# IODELAYCONFIG register map
Vendor: Texas Instruments
Registers are 32-bit, access per field, reset 0x0 unless marked. A register's access mark holds for its fields unless they carry their own. Offsets are as the file gives them; [hi:lo] are bit positions; {n}, {i} and the like mark numbered series; 'fields as' and 'values as' point back to an identical list.

## IODELAYCONFIG (part 2 of 2)
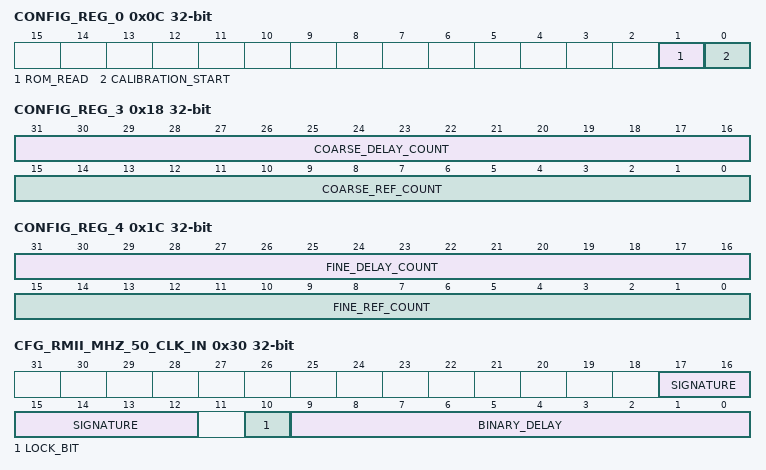
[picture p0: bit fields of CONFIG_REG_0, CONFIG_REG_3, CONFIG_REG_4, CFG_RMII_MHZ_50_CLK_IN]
0x0C CONFIG_REG_0 — Calibration Control Register
  [1] ROM_READ rw — Triggers complete ROM read when '1' is written. Cleared when ROM read is complete.
  [0] CALIBRATION_START rw — Triggers hardware calibration when '1' is written. Cleared when hardware completes calibration.
0x14 CONFIG_REG_2 reset 0x21D2 — Reference Clock Period Register.
  [15:0] REFCLK_PERIOD rw — 15:0 stores the binary equivalent of reference clock period in units of 10ps. This value (along with calibration results) is used for computing the coarse/fine element delay Example: 0xF0 means 2400ps.
0x18 CONFIG_REG_3 rw — coarse calibration results register
  [31:16] COARSE_DELAY_COUNT — Results of 16 bit counter clocked by 'delay line oscillator' clock during calibration.
  [15:0] COARSE_REF_COUNT — Results of 16 bit counter clocked by 'reference' clock during coarse calibration.
0x1C CONFIG_REG_4 rw — fine calibration results register
  [31:16] FINE_DELAY_COUNT — Results of 16 bit counter clocked by 'delay line oscillator' clock during fine calibration.
  [15:0] FINE_REF_COUNT — Results of 16 bit counter clocked by 'reference' clock during fine calibration.
0x2C CONFIG_REG_8 reset 0x1 — Global Lock Register.
  [0] GLOBAL_LOCK_BIT rw — Global Lock Bit Register. A '1' in this bit protects the writes to MMRs that store delay line select values. A '0' in this bit indicates that MMRs that store delay line select values are writeable. To write a '0' to this bit, signature of 0x5555 must be used on the MSB bits 16:1 of mdata.
0x30 CFG_RMII_MHZ_50_CLK_IN — Delay Select Value in binary coded form for cfg_RMII_MHZ_50_CLK_in interface
  [17:12] SIGNATURE rw — Write to this register will succeed only if data on these bits carries a signature of 6'h29 (6'b101001)
  [10] LOCK_BIT rw — When '1', prevents HW update to this MMR. When '0', allows HW update of this MMR.
  [9:0] BINARY_DELAY rw — Delay Select Value in binary coded form. Indicates the number of coarse (9:5) and fine (4:0) delay elements to be used on the delay line connected to this pad.
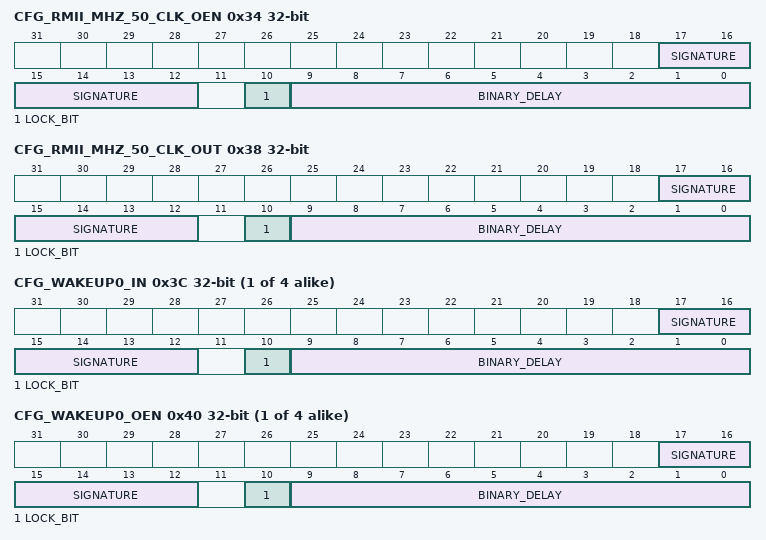
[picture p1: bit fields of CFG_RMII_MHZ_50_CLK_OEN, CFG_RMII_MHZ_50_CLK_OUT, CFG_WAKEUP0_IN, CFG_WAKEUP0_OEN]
0x34 CFG_RMII_MHZ_50_CLK_OEN — Delay Select Value in binary coded form for cfg_RMII_MHZ_50_CLK_oen interface
  fields as CFG_RMII_MHZ_50_CLK_IN
0x38 CFG_RMII_MHZ_50_CLK_OUT — Delay Select Value in binary coded form for cfg_RMII_MHZ_50_CLK_out interface
  fields as CFG_RMII_MHZ_50_CLK_IN
{0x3C+0xC*i} CFG_WAKEUP{i}_IN (i=0..3) — Delay Select Value in binary coded form for cfg_Wakeup{i}_in interface
  fields as CFG_RMII_MHZ_50_CLK_IN
{0x40+0xC*i} CFG_WAKEUP{i}_OEN (i=0..3) — Delay Select Value in binary coded form for cfg_Wakeup{i}_oen interface
  fields as CFG_RMII_MHZ_50_CLK_IN
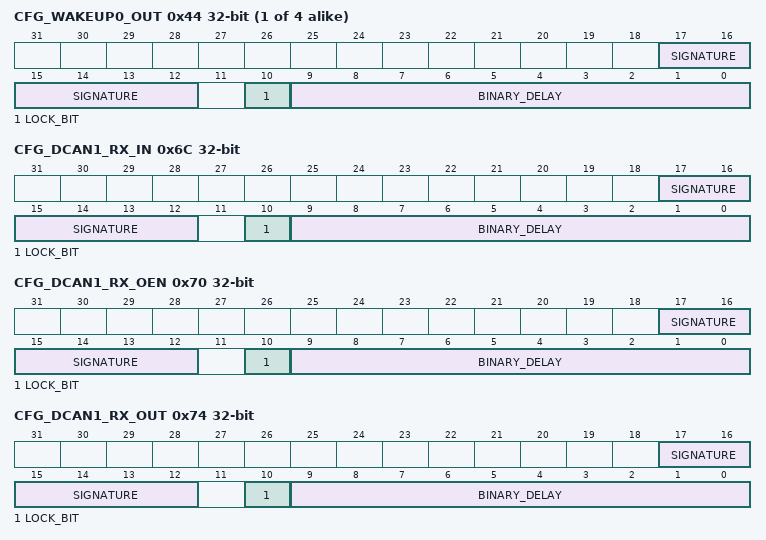
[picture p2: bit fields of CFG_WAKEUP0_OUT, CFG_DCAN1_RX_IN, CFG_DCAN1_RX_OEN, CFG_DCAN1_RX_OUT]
{0x44+0xC*i} CFG_WAKEUP{i}_OUT (i=0..3) — Delay Select Value in binary coded form for cfg_Wakeup{i}_out interface
  fields as CFG_RMII_MHZ_50_CLK_IN
0x6C CFG_DCAN1_RX_IN — Delay Select Value in binary coded form for cfg_dcan1_rx_in interface
  fields as CFG_RMII_MHZ_50_CLK_IN
0x70 CFG_DCAN1_RX_OEN — Delay Select Value in binary coded form for cfg_dcan1_rx_oen interface
  fields as CFG_RMII_MHZ_50_CLK_IN
0x74 CFG_DCAN1_RX_OUT — Delay Select Value in binary coded form for cfg_dcan1_rx_out interface
  fields as CFG_RMII_MHZ_50_CLK_IN
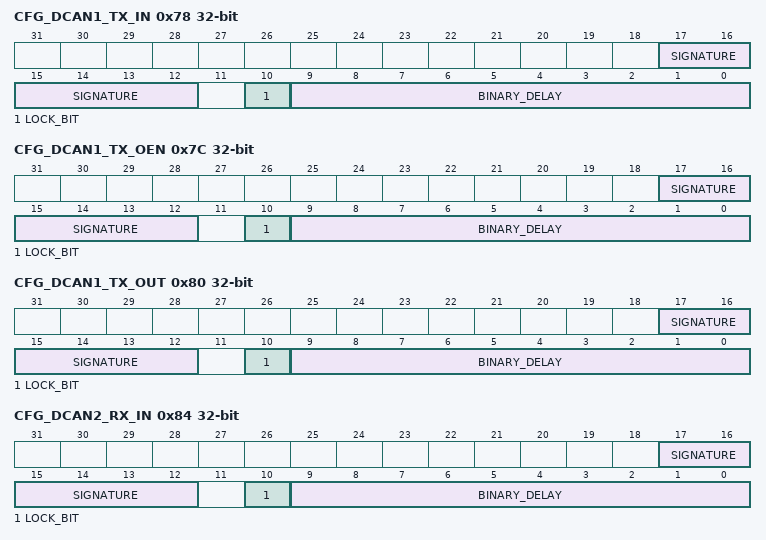
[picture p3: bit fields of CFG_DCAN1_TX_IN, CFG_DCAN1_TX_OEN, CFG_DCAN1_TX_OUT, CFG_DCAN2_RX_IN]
0x78 CFG_DCAN1_TX_IN — Delay Select Value in binary coded form for cfg_dcan1_tx_in interface
  fields as CFG_RMII_MHZ_50_CLK_IN
0x7C CFG_DCAN1_TX_OEN — Delay Select Value in binary coded form for cfg_dcan1_tx_oen interface
  fields as CFG_RMII_MHZ_50_CLK_IN
0x80 CFG_DCAN1_TX_OUT — Delay Select Value in binary coded form for cfg_dcan1_tx_out interface
  fields as CFG_RMII_MHZ_50_CLK_IN
0x84 CFG_DCAN2_RX_IN — Delay Select Value in binary coded form for cfg_dcan2_rx_in interface
  fields as CFG_RMII_MHZ_50_CLK_IN
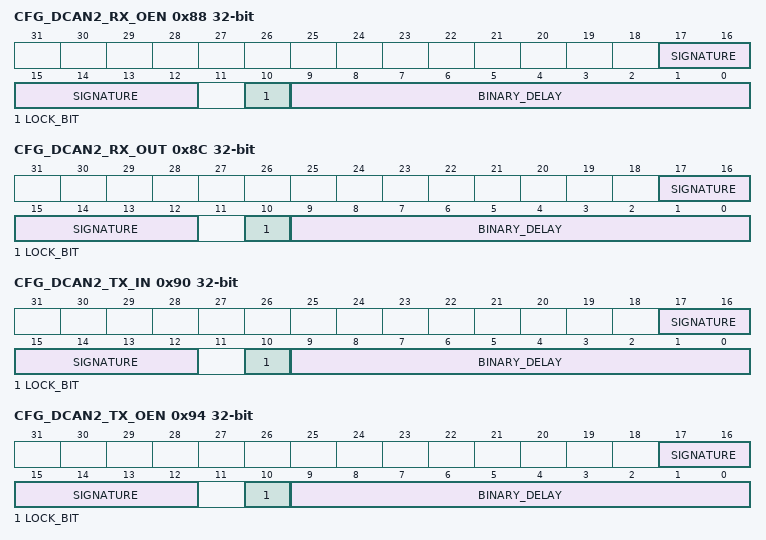
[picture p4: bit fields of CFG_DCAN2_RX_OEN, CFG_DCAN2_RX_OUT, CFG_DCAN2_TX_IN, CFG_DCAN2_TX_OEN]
0x88 CFG_DCAN2_RX_OEN — Delay Select Value in binary coded form for cfg_dcan2_rx_oen interface
  fields as CFG_RMII_MHZ_50_CLK_IN
0x8C CFG_DCAN2_RX_OUT — Delay Select Value in binary coded form for cfg_dcan2_rx_out interface
  fields as CFG_RMII_MHZ_50_CLK_IN
0x90 CFG_DCAN2_TX_IN — Delay Select Value in binary coded form for cfg_dcan2_tx_in interface
  fields as CFG_RMII_MHZ_50_CLK_IN
0x94 CFG_DCAN2_TX_OEN — Delay Select Value in binary coded form for cfg_dcan2_tx_oen interface
  fields as CFG_RMII_MHZ_50_CLK_IN
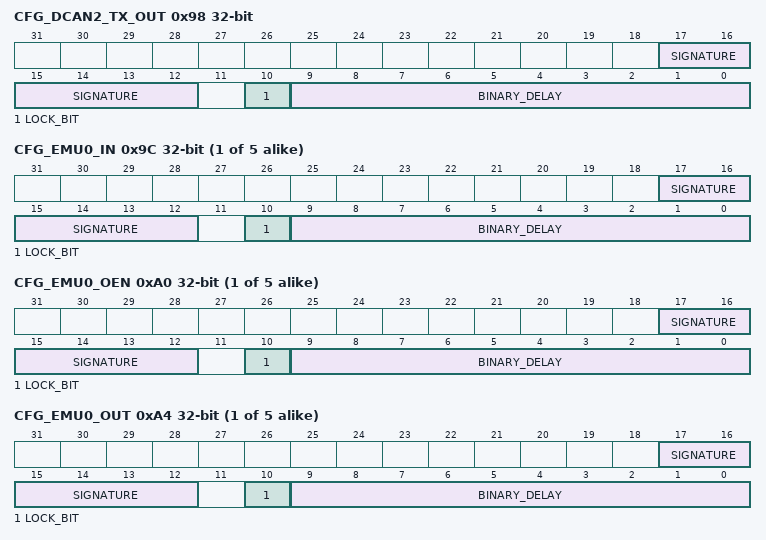
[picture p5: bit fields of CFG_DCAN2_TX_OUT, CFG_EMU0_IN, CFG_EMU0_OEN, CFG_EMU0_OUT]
0x98 CFG_DCAN2_TX_OUT — Delay Select Value in binary coded form for cfg_dcan2_tx_out interface
  fields as CFG_RMII_MHZ_50_CLK_IN
{0x9C+0xC*i} CFG_EMU{i}_IN (i=0..4) — Delay Select Value in binary coded form for cfg_emu{i}_in interface
  fields as CFG_RMII_MHZ_50_CLK_IN
{0xA0+0xC*i} CFG_EMU{i}_OEN (i=0..4) — Delay Select Value in binary coded form for cfg_emu{i}_oen interface
  fields as CFG_RMII_MHZ_50_CLK_IN
{0xA4+0xC*i} CFG_EMU{i}_OUT (i=0..4) — Delay Select Value in binary coded form for cfg_emu{i}_out interface
  fields as CFG_RMII_MHZ_50_CLK_IN
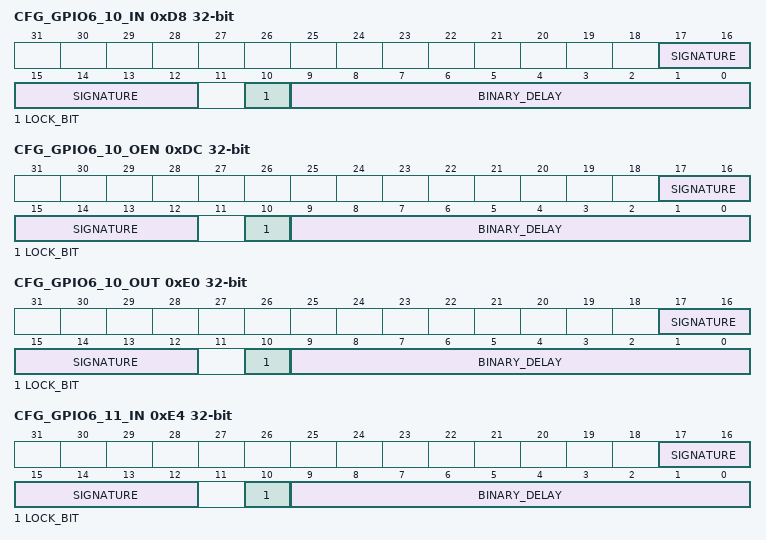
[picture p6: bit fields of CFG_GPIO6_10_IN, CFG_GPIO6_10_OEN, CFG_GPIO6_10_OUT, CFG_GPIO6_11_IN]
0xD8 CFG_GPIO6_10_IN — Delay Select Value in binary coded form for cfg_gpio6_10_in interface
  fields as CFG_RMII_MHZ_50_CLK_IN
0xDC CFG_GPIO6_10_OEN — Delay Select Value in binary coded form for cfg_gpio6_10_oen interface
  fields as CFG_RMII_MHZ_50_CLK_IN
0xE0 CFG_GPIO6_10_OUT — Delay Select Value in binary coded form for cfg_gpio6_10_out interface
  fields as CFG_RMII_MHZ_50_CLK_IN
0xE4 CFG_GPIO6_11_IN — Delay Select Value in binary coded form for cfg_gpio6_11_in interface
  fields as CFG_RMII_MHZ_50_CLK_IN
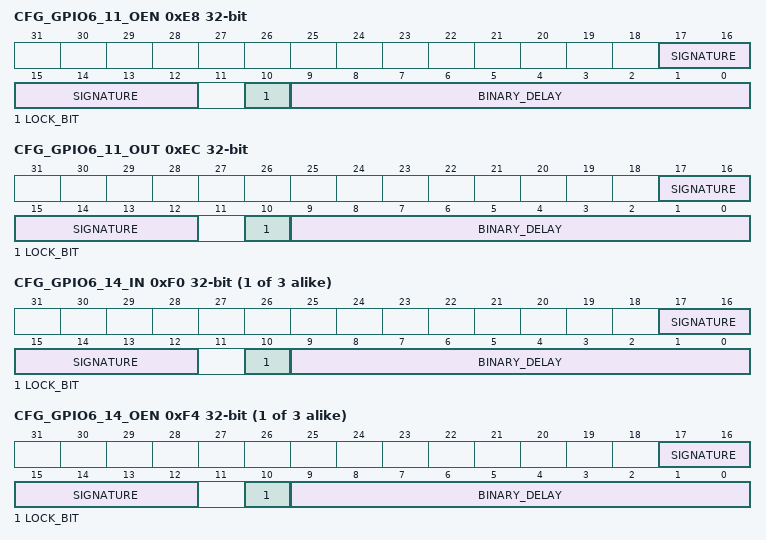
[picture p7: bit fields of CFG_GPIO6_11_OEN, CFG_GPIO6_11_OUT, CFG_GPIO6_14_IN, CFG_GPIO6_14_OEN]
0xE8 CFG_GPIO6_11_OEN — Delay Select Value in binary coded form for cfg_gpio6_11_oen interface
  fields as CFG_RMII_MHZ_50_CLK_IN
0xEC CFG_GPIO6_11_OUT — Delay Select Value in binary coded form for cfg_gpio6_11_out interface
  fields as CFG_RMII_MHZ_50_CLK_IN
{0x48+0xC*i} CFG_GPIO6_{i}_IN (i=14..16) — Delay Select Value in binary coded form for cfg_gpio6_{i}_in interface
  fields as CFG_RMII_MHZ_50_CLK_IN
{0x4C+0xC*i} CFG_GPIO6_{i}_OEN (i=14..16) — Delay Select Value in binary coded form for cfg_gpio6_{i}_oen interface
  fields as CFG_RMII_MHZ_50_CLK_IN
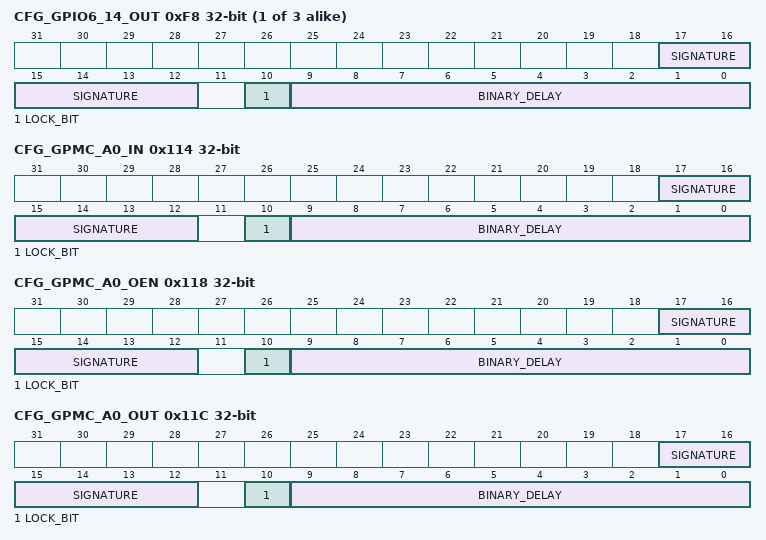
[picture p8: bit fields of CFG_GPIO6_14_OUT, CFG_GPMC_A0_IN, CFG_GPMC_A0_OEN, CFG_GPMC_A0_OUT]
{0x50+0xC*i} CFG_GPIO6_{i}_OUT (i=14..16) — Delay Select Value in binary coded form for cfg_gpio6_{i}_out interface
  fields as CFG_RMII_MHZ_50_CLK_IN
0x114 CFG_GPMC_A0_IN — Delay Select Value in binary coded form for cfg_gpmc_a0_in interface
  fields as CFG_RMII_MHZ_50_CLK_IN
0x118 CFG_GPMC_A0_OEN — Delay Select Value in binary coded form for cfg_gpmc_a0_oen interface
  fields as CFG_RMII_MHZ_50_CLK_IN
0x11C CFG_GPMC_A0_OUT — Delay Select Value in binary coded form for cfg_gpmc_a0_out interface
  fields as CFG_RMII_MHZ_50_CLK_IN
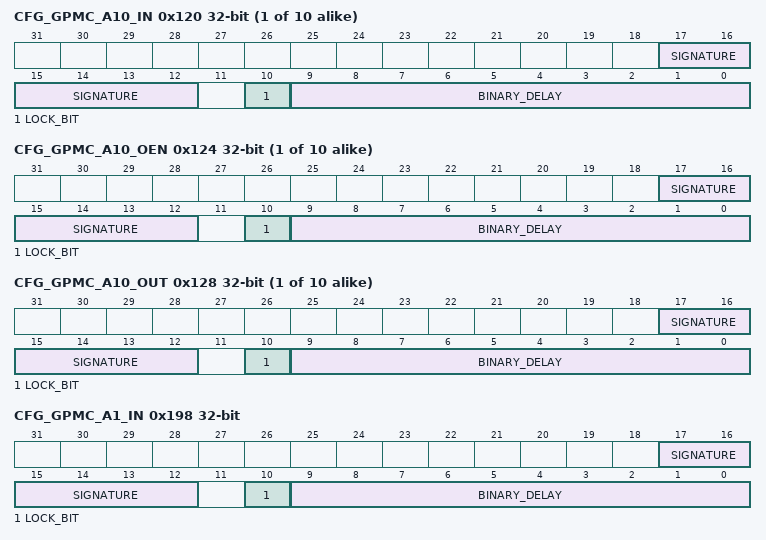
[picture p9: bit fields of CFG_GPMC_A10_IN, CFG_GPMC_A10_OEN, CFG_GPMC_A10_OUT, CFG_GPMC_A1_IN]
{0xA8+0xC*i} CFG_GPMC_A{i}_IN (i=10..19) — Delay Select Value in binary coded form for cfg_gpmc_a{i}_in interface
  fields as CFG_RMII_MHZ_50_CLK_IN
{0xAC+0xC*i} CFG_GPMC_A{i}_OEN (i=10..19) — Delay Select Value in binary coded form for cfg_gpmc_a{i}_oen interface
  fields as CFG_RMII_MHZ_50_CLK_IN
{0xB0+0xC*i} CFG_GPMC_A{i}_OUT (i=10..19) — Delay Select Value in binary coded form for cfg_gpmc_a{i}_out interface
  fields as CFG_RMII_MHZ_50_CLK_IN
0x198 CFG_GPMC_A1_IN — Delay Select Value in binary coded form for cfg_gpmc_a1_in interface
  fields as CFG_RMII_MHZ_50_CLK_IN
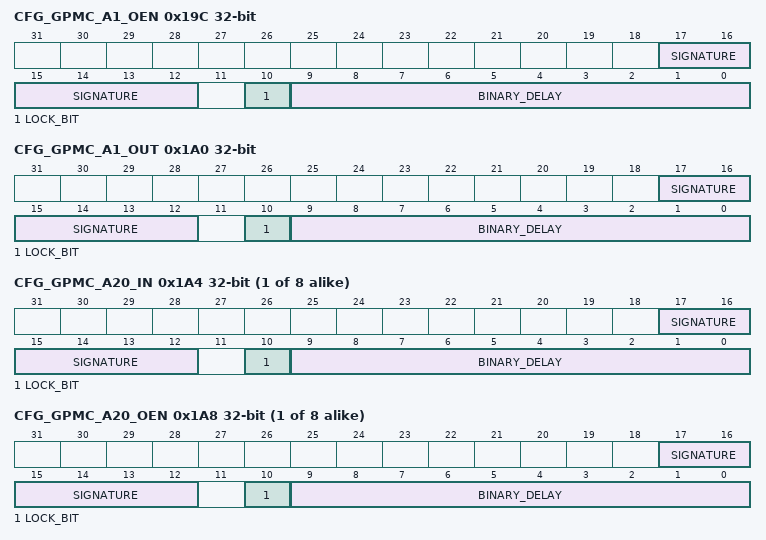
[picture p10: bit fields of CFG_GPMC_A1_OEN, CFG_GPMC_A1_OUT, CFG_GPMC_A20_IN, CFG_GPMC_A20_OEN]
0x19C CFG_GPMC_A1_OEN — Delay Select Value in binary coded form for cfg_gpmc_a1_oen interface
  fields as CFG_RMII_MHZ_50_CLK_IN
0x1A0 CFG_GPMC_A1_OUT — Delay Select Value in binary coded form for cfg_gpmc_a1_out interface
  fields as CFG_RMII_MHZ_50_CLK_IN
{0xB4+0xC*i} CFG_GPMC_A{i}_IN (i=20..27) — Delay Select Value in binary coded form for cfg_gpmc_a{i}_in interface
  fields as CFG_RMII_MHZ_50_CLK_IN
{0xB8+0xC*i} CFG_GPMC_A{i}_OEN (i=20..27) — Delay Select Value in binary coded form for cfg_gpmc_a{i}_oen interface
  fields as CFG_RMII_MHZ_50_CLK_IN
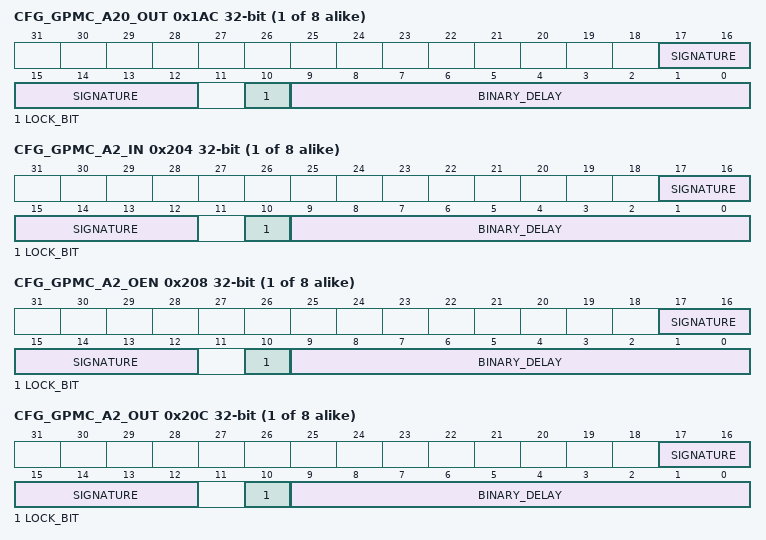
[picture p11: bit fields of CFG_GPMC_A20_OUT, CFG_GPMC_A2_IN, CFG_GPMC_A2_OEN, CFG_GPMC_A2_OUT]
{0xBC+0xC*i} CFG_GPMC_A{i}_OUT (i=20..27) — Delay Select Value in binary coded form for cfg_gpmc_a{i}_out interface
  fields as CFG_RMII_MHZ_50_CLK_IN
{0x1EC+0xC*i} CFG_GPMC_A{i}_IN (i=2..9) — Delay Select Value in binary coded form for cfg_gpmc_a{i}_in interface
  fields as CFG_RMII_MHZ_50_CLK_IN
{0x1F0+0xC*i} CFG_GPMC_A{i}_OEN (i=2..9) — Delay Select Value in binary coded form for cfg_gpmc_a{i}_oen interface
  fields as CFG_RMII_MHZ_50_CLK_IN
{0x1F4+0xC*i} CFG_GPMC_A{i}_OUT (i=2..9) — Delay Select Value in binary coded form for cfg_gpmc_a{i}_out interface
  fields as CFG_RMII_MHZ_50_CLK_IN
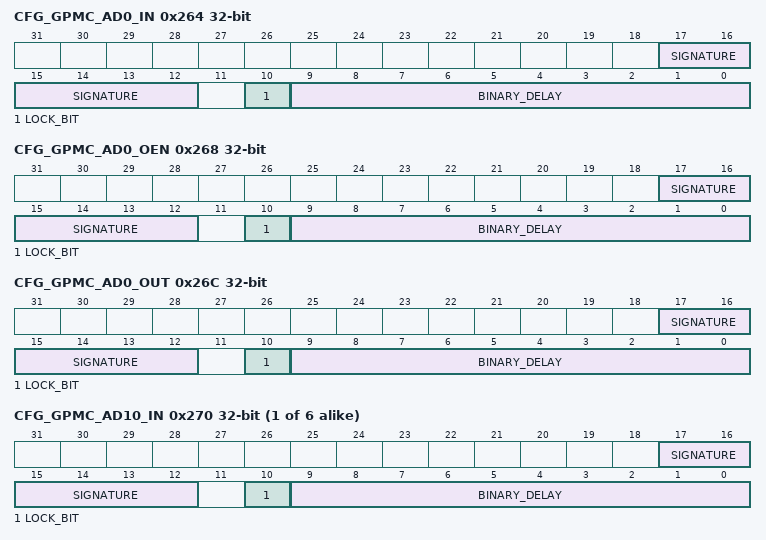
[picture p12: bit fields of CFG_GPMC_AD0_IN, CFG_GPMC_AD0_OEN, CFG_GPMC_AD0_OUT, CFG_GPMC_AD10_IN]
0x264 CFG_GPMC_AD0_IN — Delay Select Value in binary coded form for cfg_gpmc_ad0_in interface
  fields as CFG_RMII_MHZ_50_CLK_IN
0x268 CFG_GPMC_AD0_OEN — Delay Select Value in binary coded form for cfg_gpmc_ad0_oen interface
  fields as CFG_RMII_MHZ_50_CLK_IN
0x26C CFG_GPMC_AD0_OUT — Delay Select Value in binary coded form for cfg_gpmc_ad0_out interface
  fields as CFG_RMII_MHZ_50_CLK_IN
{0x1F8+0xC*i} CFG_GPMC_AD{i}_IN (i=10..15) — Delay Select Value in binary coded form for cfg_gpmc_ad{i}_in interface
  fields as CFG_RMII_MHZ_50_CLK_IN
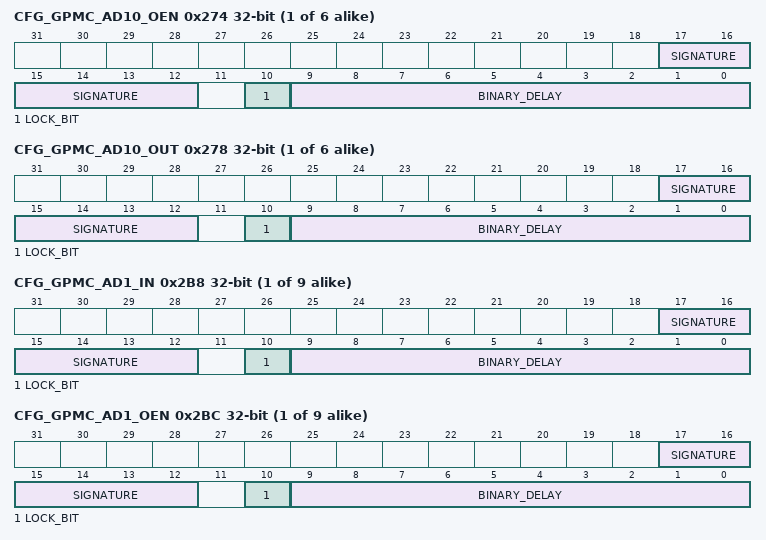
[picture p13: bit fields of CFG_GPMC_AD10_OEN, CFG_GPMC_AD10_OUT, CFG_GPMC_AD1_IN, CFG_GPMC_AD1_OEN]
{0x1FC+0xC*i} CFG_GPMC_AD{i}_OEN (i=10..15) — Delay Select Value in binary coded form for cfg_gpmc_ad{i}_oen interface
  fields as CFG_RMII_MHZ_50_CLK_IN
{0x200+0xC*i} CFG_GPMC_AD{i}_OUT (i=10..15) — Delay Select Value in binary coded form for cfg_gpmc_ad{i}_out interface
  fields as CFG_RMII_MHZ_50_CLK_IN
{0x2AC+0xC*i} CFG_GPMC_AD{i}_IN (i=1..9) — Delay Select Value in binary coded form for cfg_gpmc_ad{i}_in interface
  fields as CFG_RMII_MHZ_50_CLK_IN
{0x2B0+0xC*i} CFG_GPMC_AD{i}_OEN (i=1..9) — Delay Select Value in binary coded form for cfg_gpmc_ad{i}_oen interface
  fields as CFG_RMII_MHZ_50_CLK_IN
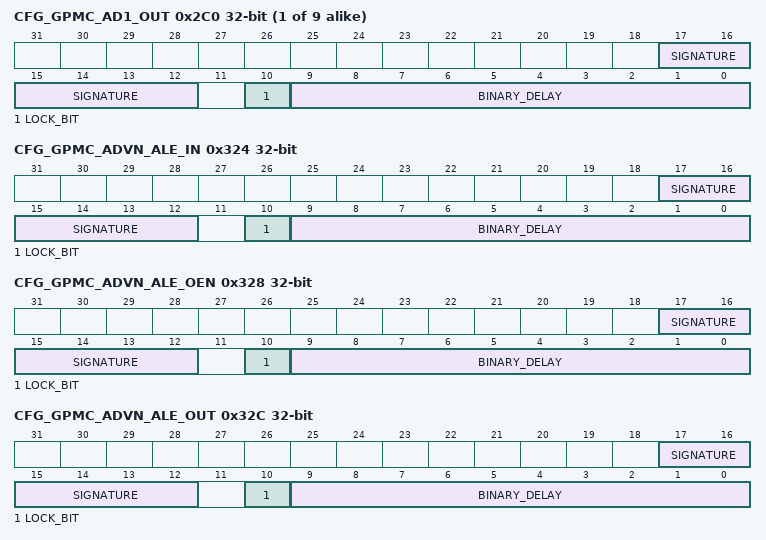
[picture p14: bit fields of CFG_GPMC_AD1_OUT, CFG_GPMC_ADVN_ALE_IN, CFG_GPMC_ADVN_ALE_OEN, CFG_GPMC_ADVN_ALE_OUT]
{0x2B4+0xC*i} CFG_GPMC_AD{i}_OUT (i=1..9) — Delay Select Value in binary coded form for cfg_gpmc_ad{i}_out interface
  fields as CFG_RMII_MHZ_50_CLK_IN
0x324 CFG_GPMC_ADVN_ALE_IN — Delay Select Value in binary coded form for cfg_gpmc_advn_ale_in interface
  fields as CFG_RMII_MHZ_50_CLK_IN
0x328 CFG_GPMC_ADVN_ALE_OEN — Delay Select Value in binary coded form for cfg_gpmc_advn_ale_oen interface
  fields as CFG_RMII_MHZ_50_CLK_IN
0x32C CFG_GPMC_ADVN_ALE_OUT — Delay Select Value in binary coded form for cfg_gpmc_advn_ale_out interface
  fields as CFG_RMII_MHZ_50_CLK_IN
0x330 CFG_GPMC_BEN0_IN — Delay Select Value in binary coded form for cfg_gpmc_ben0_in interface
  fields as CFG_RMII_MHZ_50_CLK_IN
0x334 CFG_GPMC_BEN0_OEN — Delay Select Value in binary coded form for cfg_gpmc_ben0_oen interface
  fields as CFG_RMII_MHZ_50_CLK_IN
0x338 CFG_GPMC_BEN0_OUT — Delay Select Value in binary coded form for cfg_gpmc_ben0_out interface
  fields as CFG_RMII_MHZ_50_CLK_IN
0x33C CFG_GPMC_BEN1_IN — Delay Select Value in binary coded form for cfg_gpmc_ben1_in interface
  fields as CFG_RMII_MHZ_50_CLK_IN
0x340 CFG_GPMC_BEN1_OEN — Delay Select Value in binary coded form for cfg_gpmc_ben1_oen interface
  fields as CFG_RMII_MHZ_50_CLK_IN
0x344 CFG_GPMC_BEN1_OUT — Delay Select Value in binary coded form for cfg_gpmc_ben1_out interface
  fields as CFG_RMII_MHZ_50_CLK_IN
0x348 CFG_GPMC_CLK_IN — Delay Select Value in binary coded form for cfg_gpmc_clk_in interface
  fields as CFG_RMII_MHZ_50_CLK_IN
0x34C CFG_GPMC_CLK_OEN — Delay Select Value in binary coded form for cfg_gpmc_clk_oen interface
  fields as CFG_RMII_MHZ_50_CLK_IN
0x350 CFG_GPMC_CLK_OUT — Delay Select Value in binary coded form for cfg_gpmc_clk_out interface
  fields as CFG_RMII_MHZ_50_CLK_IN
{0x354+0xC*i} CFG_GPMC_CS{i}_IN (i=0..3) — Delay Select Value in binary coded form for cfg_gpmc_cs{i}_in interface
  fields as CFG_RMII_MHZ_50_CLK_IN
{0x358+0xC*i} CFG_GPMC_CS{i}_OEN (i=0..3) — Delay Select Value in binary coded form for cfg_gpmc_cs{i}_oen interface
  fields as CFG_RMII_MHZ_50_CLK_IN
{0x35C+0xC*i} CFG_GPMC_CS{i}_OUT (i=0..3) — Delay Select Value in binary coded form for cfg_gpmc_cs{i}_out interface
  fields as CFG_RMII_MHZ_50_CLK_IN
0x384 CFG_GPMC_OEN_REN_IN — Delay Select Value in binary coded form for cfg_gpmc_oen_ren_in interface
  fields as CFG_RMII_MHZ_50_CLK_IN
0x388 CFG_GPMC_OEN_REN_OEN — Delay Select Value in binary coded form for cfg_gpmc_oen_ren_oen interface
  fields as CFG_RMII_MHZ_50_CLK_IN
0x38C CFG_GPMC_OEN_REN_OUT — Delay Select Value in binary coded form for cfg_gpmc_oen_ren_out interface
  fields as CFG_RMII_MHZ_50_CLK_IN
0x390 CFG_GPMC_WAIT0_IN — Delay Select Value in binary coded form for cfg_gpmc_wait0_in interface
  fields as CFG_RMII_MHZ_50_CLK_IN
0x394 CFG_GPMC_WAIT0_OEN — Delay Select Value in binary coded form for cfg_gpmc_wait0_oen interface
  fields as CFG_RMII_MHZ_50_CLK_IN
0x398 CFG_GPMC_WAIT0_OUT — Delay Select Value in binary coded form for cfg_gpmc_wait0_out interface
  fields as CFG_RMII_MHZ_50_CLK_IN
0x39C CFG_GPMC_WEN_IN — Delay Select Value in binary coded form for cfg_gpmc_wen_in interface
  fields as CFG_RMII_MHZ_50_CLK_IN
0x3A0 CFG_GPMC_WEN_OEN — Delay Select Value in binary coded form for cfg_gpmc_wen_oen interface
  fields as CFG_RMII_MHZ_50_CLK_IN
0x3A4 CFG_GPMC_WEN_OUT — Delay Select Value in binary coded form for cfg_gpmc_wen_out interface
  fields as CFG_RMII_MHZ_50_CLK_IN
0x3A8 CFG_MCASP1_ACLKR_IN — Delay Select Value in binary coded form for cfg_mcasp1_aclkr_in interface
  fields as CFG_RMII_MHZ_50_CLK_IN
0x3AC CFG_MCASP1_ACLKR_OEN — Delay Select Value in binary coded form for cfg_mcasp1_aclkr_oen interface
  fields as CFG_RMII_MHZ_50_CLK_IN
0x3B0 CFG_MCASP1_ACLKR_OUT — Delay Select Value in binary coded form for cfg_mcasp1_aclkr_out interface
  fields as CFG_RMII_MHZ_50_CLK_IN
0x3B4 CFG_MCASP1_ACLKX_IN — Delay Select Value in binary coded form for cfg_mcasp1_aclkx_in interface
  fields as CFG_RMII_MHZ_50_CLK_IN
0x3B8 CFG_MCASP1_ACLKX_OEN — Delay Select Value in binary coded form for cfg_mcasp1_aclkx_oen interface
  fields as CFG_RMII_MHZ_50_CLK_IN
0x3BC CFG_MCASP1_ACLKX_OUT — Delay Select Value in binary coded form for cfg_mcasp1_aclkx_out interface
  fields as CFG_RMII_MHZ_50_CLK_IN
0x3C0 CFG_MCASP1_AXR0_IN — Delay Select Value in binary coded form for cfg_mcasp1_axr0_in interface
  fields as CFG_RMII_MHZ_50_CLK_IN
0x3C4 CFG_MCASP1_AXR0_OEN — Delay Select Value in binary coded form for cfg_mcasp1_axr0_oen interface
  fields as CFG_RMII_MHZ_50_CLK_IN
0x3C8 CFG_MCASP1_AXR0_OUT — Delay Select Value in binary coded form for cfg_mcasp1_axr0_out interface
  fields as CFG_RMII_MHZ_50_CLK_IN
{0x354+0xC*i} CFG_MCASP1_AXR{i}_IN (i=10..15) — Delay Select Value in binary coded form for cfg_mcasp1_axr{i}_in interface
  fields as CFG_RMII_MHZ_50_CLK_IN
{0x358+0xC*i} CFG_MCASP1_AXR{i}_OEN (i=10..15) — Delay Select Value in binary coded form for cfg_mcasp1_axr{i}_oen interface
  fields as CFG_RMII_MHZ_50_CLK_IN
{0x35C+0xC*i} CFG_MCASP1_AXR{i}_OUT (i=10..15) — Delay Select Value in binary coded form for cfg_mcasp1_axr{i}_out interface
  fields as CFG_RMII_MHZ_50_CLK_IN
{0x408+0xC*i} CFG_MCASP1_AXR{i}_IN (i=1..9) — Delay Select Value in binary coded form for cfg_mcasp1_axr{i}_in interface
  fields as CFG_RMII_MHZ_50_CLK_IN
{0x40C+0xC*i} CFG_MCASP1_AXR{i}_OEN (i=1..9) — Delay Select Value in binary coded form for cfg_mcasp1_axr{i}_oen interface
  fields as CFG_RMII_MHZ_50_CLK_IN
{0x410+0xC*i} CFG_MCASP1_AXR{i}_OUT (i=1..9) — Delay Select Value in binary coded form for cfg_mcasp1_axr{i}_out interface
  fields as CFG_RMII_MHZ_50_CLK_IN
0x480 CFG_MCASP1_FSR_IN — Delay Select Value in binary coded form for cfg_mcasp1_fsr_in interface
  fields as CFG_RMII_MHZ_50_CLK_IN
0x484 CFG_MCASP1_FSR_OEN — Delay Select Value in binary coded form for cfg_mcasp1_fsr_oen interface
  fields as CFG_RMII_MHZ_50_CLK_IN
0x488 CFG_MCASP1_FSR_OUT — Delay Select Value in binary coded form for cfg_mcasp1_fsr_out interface
  fields as CFG_RMII_MHZ_50_CLK_IN
0x48C CFG_MCASP1_FSX_IN — Delay Select Value in binary coded form for cfg_mcasp1_fsx_in interface
  fields as CFG_RMII_MHZ_50_CLK_IN
0x490 CFG_MCASP1_FSX_OEN — Delay Select Value in binary coded form for cfg_mcasp1_fsx_oen interface
  fields as CFG_RMII_MHZ_50_CLK_IN
0x494 CFG_MCASP1_FSX_OUT — Delay Select Value in binary coded form for cfg_mcasp1_fsx_out interface
  fields as CFG_RMII_MHZ_50_CLK_IN
0x498 CFG_MCASP2_ACLKR_IN — Delay Select Value in binary coded form for cfg_mcasp2_aclkr_in interface
  fields as CFG_RMII_MHZ_50_CLK_IN
0x49C CFG_MCASP2_ACLKR_OEN — Delay Select Value in binary coded form for cfg_mcasp2_aclkr_oen interface
  fields as CFG_RMII_MHZ_50_CLK_IN
0x4A0 CFG_MCASP2_ACLKR_OUT — Delay Select Value in binary coded form for cfg_mcasp2_aclkr_out interface
  fields as CFG_RMII_MHZ_50_CLK_IN
0x4A4 CFG_MCASP2_ACLKX_IN — Delay Select Value in binary coded form for cfg_mcasp2_aclkx_in interface
  fields as CFG_RMII_MHZ_50_CLK_IN
0x4A8 CFG_MCASP2_ACLKX_OEN — Delay Select Value in binary coded form for cfg_mcasp2_aclkx_oen interface
  fields as CFG_RMII_MHZ_50_CLK_IN
0x4AC CFG_MCASP2_ACLKX_OUT — Delay Select Value in binary coded form for cfg_mcasp2_aclkx_out interface
  fields as CFG_RMII_MHZ_50_CLK_IN
{0x4B0+0xC*i} CFG_MCASP2_AXR{i}_IN (i=0..7) — Delay Select Value in binary coded form for cfg_mcasp2_axr{i}_in interface
  fields as CFG_RMII_MHZ_50_CLK_IN
{0x4B4+0xC*i} CFG_MCASP2_AXR{i}_OEN (i=0..7) — Delay Select Value in binary coded form for cfg_mcasp2_axr{i}_oen interface
  fields as CFG_RMII_MHZ_50_CLK_IN
{0x4B8+0xC*i} CFG_MCASP2_AXR{i}_OUT (i=0..7) — Delay Select Value in binary coded form for cfg_mcasp2_axr{i}_out interface
  fields as CFG_RMII_MHZ_50_CLK_IN
0x510 CFG_MCASP2_FSR_IN — Delay Select Value in binary coded form for cfg_mcasp2_fsr_in interface
  fields as CFG_RMII_MHZ_50_CLK_IN
0x514 CFG_MCASP2_FSR_OEN — Delay Select Value in binary coded form for cfg_mcasp2_fsr_oen interface
  fields as CFG_RMII_MHZ_50_CLK_IN
0x518 CFG_MCASP2_FSR_OUT — Delay Select Value in binary coded form for cfg_mcasp2_fsr_out interface
  fields as CFG_RMII_MHZ_50_CLK_IN
{0x4BC+0x30*i} CFG_MCASP{i}_FSX_IN (i=2..5) — Delay Select Value in binary coded form for cfg_mcasp{i}_fsx_in interface
  fields as CFG_RMII_MHZ_50_CLK_IN
{0x4C0+0x30*i} CFG_MCASP{i}_FSX_OEN (i=2..5) — Delay Select Value in binary coded form for cfg_mcasp{i}_fsx_oen interface
  fields as CFG_RMII_MHZ_50_CLK_IN
{0x4C4+0x30*i} CFG_MCASP{i}_FSX_OUT (i=2..5) — Delay Select Value in binary coded form for cfg_mcasp{i}_fsx_out interface
  fields as CFG_RMII_MHZ_50_CLK_IN
{0x498+0x30*i} CFG_MCASP{i}_ACLKX_IN (i=3..5) — Delay Select Value in binary coded form for cfg_mcasp{i}_aclkx_in interface
  fields as CFG_RMII_MHZ_50_CLK_IN
{0x49C+0x30*i} CFG_MCASP{i}_ACLKX_OEN (i=3..5) — Delay Select Value in binary coded form for cfg_mcasp{i}_aclkx_oen interface
  fields as CFG_RMII_MHZ_50_CLK_IN
{0x4A0+0x30*i} CFG_MCASP{i}_ACLKX_OUT (i=3..5) — Delay Select Value in binary coded form for cfg_mcasp{i}_aclkx_out interface
  fields as CFG_RMII_MHZ_50_CLK_IN
0x534 CFG_MCASP3_AXR0_IN — Delay Select Value in binary coded form for cfg_mcasp3_axr0_in interface
  fields as CFG_RMII_MHZ_50_CLK_IN
0x538 CFG_MCASP3_AXR0_OEN — Delay Select Value in binary coded form for cfg_mcasp3_axr0_oen interface
  fields as CFG_RMII_MHZ_50_CLK_IN
0x53C CFG_MCASP3_AXR0_OUT — Delay Select Value in binary coded form for cfg_mcasp3_axr0_out interface
  fields as CFG_RMII_MHZ_50_CLK_IN
0x540 CFG_MCASP3_AXR1_IN — Delay Select Value in binary coded form for cfg_mcasp3_axr1_in interface
  fields as CFG_RMII_MHZ_50_CLK_IN
0x544 CFG_MCASP3_AXR1_OEN — Delay Select Value in binary coded form for cfg_mcasp3_axr1_oen interface
  fields as CFG_RMII_MHZ_50_CLK_IN
0x548 CFG_MCASP3_AXR1_OUT — Delay Select Value in binary coded form for cfg_mcasp3_axr1_out interface
  fields as CFG_RMII_MHZ_50_CLK_IN
0x564 CFG_MCASP4_AXR0_IN — Delay Select Value in binary coded form for cfg_mcasp4_axr0_in interface
  fields as CFG_RMII_MHZ_50_CLK_IN
0x568 CFG_MCASP4_AXR0_OEN — Delay Select Value in binary coded form for cfg_mcasp4_axr0_oen interface
  fields as CFG_RMII_MHZ_50_CLK_IN
0x56C CFG_MCASP4_AXR0_OUT — Delay Select Value in binary coded form for cfg_mcasp4_axr0_out interface
  fields as CFG_RMII_MHZ_50_CLK_IN
0x570 CFG_MCASP4_AXR1_IN — Delay Select Value in binary coded form for cfg_mcasp4_axr1_in interface
  fields as CFG_RMII_MHZ_50_CLK_IN
0x574 CFG_MCASP4_AXR1_OEN — Delay Select Value in binary coded form for cfg_mcasp4_axr1_oen interface
  fields as CFG_RMII_MHZ_50_CLK_IN
0x578 CFG_MCASP4_AXR1_OUT — Delay Select Value in binary coded form for cfg_mcasp4_axr1_out interface
  fields as CFG_RMII_MHZ_50_CLK_IN
0x594 CFG_MCASP5_AXR0_IN — Delay Select Value in binary coded form for cfg_mcasp5_axr0_in interface
  fields as CFG_RMII_MHZ_50_CLK_IN
0x598 CFG_MCASP5_AXR0_OEN — Delay Select Value in binary coded form for cfg_mcasp5_axr0_oen interface
  fields as CFG_RMII_MHZ_50_CLK_IN
0x59C CFG_MCASP5_AXR0_OUT — Delay Select Value in binary coded form for cfg_mcasp5_axr0_out interface
  fields as CFG_RMII_MHZ_50_CLK_IN
0x5A0 CFG_MCASP5_AXR1_IN — Delay Select Value in binary coded form for cfg_mcasp5_axr1_in interface
  fields as CFG_RMII_MHZ_50_CLK_IN
0x5A4 CFG_MCASP5_AXR1_OEN — Delay Select Value in binary coded form for cfg_mcasp5_axr1_oen interface
  fields as CFG_RMII_MHZ_50_CLK_IN
0x5A8 CFG_MCASP5_AXR1_OUT — Delay Select Value in binary coded form for cfg_mcasp5_axr1_out interface
  fields as CFG_RMII_MHZ_50_CLK_IN
0x5B8 CFG_MDIO_D_IN — Delay Select Value in binary coded form for cfg_mdio_d_in interface
  fields as CFG_RMII_MHZ_50_CLK_IN
0x5BC CFG_MDIO_D_OEN — Delay Select Value in binary coded form for cfg_mdio_d_oen interface
  fields as CFG_RMII_MHZ_50_CLK_IN
0x5C0 CFG_MDIO_D_OUT — Delay Select Value in binary coded form for cfg_mdio_d_out interface
  fields as CFG_RMII_MHZ_50_CLK_IN
0x5C4 CFG_MDIO_MCLK_IN — Delay Select Value in binary coded form for cfg_mdio_mclk_in interface
  fields as CFG_RMII_MHZ_50_CLK_IN
0x5C8 CFG_MDIO_MCLK_OEN — Delay Select Value in binary coded form for cfg_mdio_mclk_oen interface
  fields as CFG_RMII_MHZ_50_CLK_IN
0x5CC CFG_MDIO_MCLK_OUT — Delay Select Value in binary coded form for cfg_mdio_mclk_out interface
  fields as CFG_RMII_MHZ_50_CLK_IN
0x5D0 CFG_MLBP_CLK_N_IN — Delay Select Value in binary coded form for cfg_mlbp_clk_n_in interface
  fields as CFG_RMII_MHZ_50_CLK_IN
0x5D4 CFG_MLBP_CLK_N_OEN — Delay Select Value in binary coded form for cfg_mlbp_clk_n_oen interface
  fields as CFG_RMII_MHZ_50_CLK_IN
0x5D8 CFG_MLBP_CLK_N_OUT — Delay Select Value in binary coded form for cfg_mlbp_clk_n_out interface
  fields as CFG_RMII_MHZ_50_CLK_IN
0x5DC CFG_MLBP_CLK_P_IN — Delay Select Value in binary coded form for cfg_mlbp_clk_p_in interface
  fields as CFG_RMII_MHZ_50_CLK_IN
0x5E0 CFG_MLBP_CLK_P_OEN — Delay Select Value in binary coded form for cfg_mlbp_clk_p_oen interface
  fields as CFG_RMII_MHZ_50_CLK_IN
0x5E4 CFG_MLBP_CLK_P_OUT — Delay Select Value in binary coded form for cfg_mlbp_clk_p_out interface
  fields as CFG_RMII_MHZ_50_CLK_IN
0x5E8 CFG_MLBP_DAT_N_IN — Delay Select Value in binary coded form for cfg_mlbp_dat_n_in interface
  fields as CFG_RMII_MHZ_50_CLK_IN
0x5EC CFG_MLBP_DAT_N_OEN — Delay Select Value in binary coded form for cfg_mlbp_dat_n_oen interface
  fields as CFG_RMII_MHZ_50_CLK_IN
0x5F0 CFG_MLBP_DAT_N_OUT — Delay Select Value in binary coded form for cfg_mlbp_dat_n_out interface
  fields as CFG_RMII_MHZ_50_CLK_IN
0x5F4 CFG_MLBP_DAT_P_IN — Delay Select Value in binary coded form for cfg_mlbp_dat_p_in interface
  fields as CFG_RMII_MHZ_50_CLK_IN
0x5F8 CFG_MLBP_DAT_P_OEN — Delay Select Value in binary coded form for cfg_mlbp_dat_p_oen interface
  fields as CFG_RMII_MHZ_50_CLK_IN
0x5FC CFG_MLBP_DAT_P_OUT — Delay Select Value in binary coded form for cfg_mlbp_dat_p_out interface
  fields as CFG_RMII_MHZ_50_CLK_IN
0x600 CFG_MLBP_SIG_N_IN — Delay Select Value in binary coded form for cfg_mlbp_sig_n_in interface
  fields as CFG_RMII_MHZ_50_CLK_IN
0x604 CFG_MLBP_SIG_N_OEN — Delay Select Value in binary coded form for cfg_mlbp_sig_n_oen interface
  fields as CFG_RMII_MHZ_50_CLK_IN
0x608 CFG_MLBP_SIG_N_OUT — Delay Select Value in binary coded form for cfg_mlbp_sig_n_out interface
  fields as CFG_RMII_MHZ_50_CLK_IN
0x60C CFG_MLBP_SIG_P_IN — Delay Select Value in binary coded form for cfg_mlbp_sig_p_in interface
  fields as CFG_RMII_MHZ_50_CLK_IN
0x610 CFG_MLBP_SIG_P_OEN — Delay Select Value in binary coded form for cfg_mlbp_sig_p_oen interface
  fields as CFG_RMII_MHZ_50_CLK_IN
0x614 CFG_MLBP_SIG_P_OUT — Delay Select Value in binary coded form for cfg_mlbp_sig_p_out interface
  fields as CFG_RMII_MHZ_50_CLK_IN
0x618 CFG_MMC1_CLK_IN — Delay Select Value in binary coded form for cfg_mmc1_clk_in interface
  fields as CFG_RMII_MHZ_50_CLK_IN
0x61C CFG_MMC1_CLK_OEN — Delay Select Value in binary coded form for cfg_mmc1_clk_oen interface
  fields as CFG_RMII_MHZ_50_CLK_IN
0x620 CFG_MMC1_CLK_OUT — Delay Select Value in binary coded form for cfg_mmc1_clk_out interface
  fields as CFG_RMII_MHZ_50_CLK_IN
0x624 CFG_MMC1_CMD_IN — Delay Select Value in binary coded form for cfg_mmc1_cmd_in interface
  fields as CFG_RMII_MHZ_50_CLK_IN
0x628 CFG_MMC1_CMD_OEN — Delay Select Value in binary coded form for cfg_mmc1_cmd_oen interface
  fields as CFG_RMII_MHZ_50_CLK_IN
0x62C CFG_MMC1_CMD_OUT — Delay Select Value in binary coded form for cfg_mmc1_cmd_out interface
  fields as CFG_RMII_MHZ_50_CLK_IN
{0x630+0xC*i} CFG_MMC1_DAT{i}_IN (i=0..3) — Delay Select Value in binary coded form for cfg_mmc1_dat{i}_in interface
  fields as CFG_RMII_MHZ_50_CLK_IN
{0x634+0xC*i} CFG_MMC1_DAT{i}_OEN (i=0..3) — Delay Select Value in binary coded form for cfg_mmc1_dat{i}_oen interface
  fields as CFG_RMII_MHZ_50_CLK_IN
{0x638+0xC*i} CFG_MMC1_DAT{i}_OUT (i=0..3) — Delay Select Value in binary coded form for cfg_mmc1_dat{i}_out interface
  fields as CFG_RMII_MHZ_50_CLK_IN
0x660 CFG_MMC1_SDCD_IN — Delay Select Value in binary coded form for cfg_mmc1_sdcd_in interface
  fields as CFG_RMII_MHZ_50_CLK_IN
0x664 CFG_MMC1_SDCD_OEN — Delay Select Value in binary coded form for cfg_mmc1_sdcd_oen interface
  fields as CFG_RMII_MHZ_50_CLK_IN
0x668 CFG_MMC1_SDCD_OUT — Delay Select Value in binary coded form for cfg_mmc1_sdcd_out interface
  fields as CFG_RMII_MHZ_50_CLK_IN
0x66C CFG_MMC1_SDWP_IN — Delay Select Value in binary coded form for cfg_mmc1_sdwp_in interface
  fields as CFG_RMII_MHZ_50_CLK_IN
0x670 CFG_MMC1_SDWP_OEN — Delay Select Value in binary coded form for cfg_mmc1_sdwp_oen interface
  fields as CFG_RMII_MHZ_50_CLK_IN
0x674 CFG_MMC1_SDWP_OUT — Delay Select Value in binary coded form for cfg_mmc1_sdwp_out interface
  fields as CFG_RMII_MHZ_50_CLK_IN
0x678 CFG_MMC3_CLK_IN — Delay Select Value in binary coded form for cfg_mmc3_clk_in interface
  fields as CFG_RMII_MHZ_50_CLK_IN
0x67C CFG_MMC3_CLK_OEN — Delay Select Value in binary coded form for cfg_mmc3_clk_oen interface
  fields as CFG_RMII_MHZ_50_CLK_IN
0x680 CFG_MMC3_CLK_OUT — Delay Select Value in binary coded form for cfg_mmc3_clk_out interface
  fields as CFG_RMII_MHZ_50_CLK_IN
0x684 CFG_MMC3_CMD_IN — Delay Select Value in binary coded form for cfg_mmc3_cmd_in interface
  fields as CFG_RMII_MHZ_50_CLK_IN
